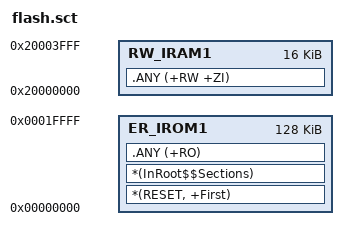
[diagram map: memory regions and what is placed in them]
; *****************************************************************************
;  flash.sct — 正式固件链接到内部 Flash
;
;  Flash: 0x00000000 ~ 0x00020000 (128KB)
;  RAM:   0x20000000 ~ 0x20004000 (16KB)
; *****************************************************************************

LR_IROM1 0x00000000 0x00020000  {
  ER_IROM1 0x00000000 0x00020000  {
    *(RESET, +First)
    *(InRoot$$Sections)
    .ANY (+RO)
  }
  RW_IRAM1 0x20000000 0x00004000  {
    .ANY (+RW +ZI)
  }
}
